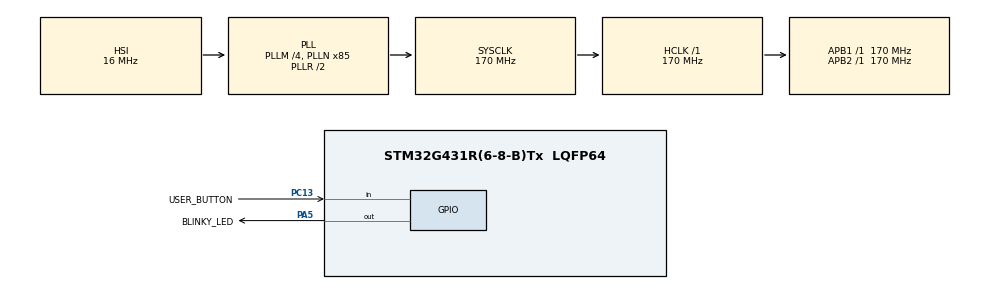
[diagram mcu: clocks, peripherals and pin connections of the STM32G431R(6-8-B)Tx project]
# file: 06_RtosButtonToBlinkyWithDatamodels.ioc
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FREERTOS.Tasks01=defaultTask,24,128,StartDefaultTask,Default,NULL,Dynamic,NULL,NULL;Input_Handler,24,128,InputHandler,Default,NULL,Dynamic,NULL,NULL;Output_Handler,24,128,OutputHandler,Default,NULL,Dynamic,NULL,NULL
FREERTOS.configUSE_NEWLIB_REENTRANT=1
Mcu.Family=STM32G4
Mcu.Name=STM32G431R(6-8-B)Tx
Mcu.Package=LQFP64
NVIC.PriorityGroup=NVIC_PRIORITYGROUP_4
NVIC.TIM1_TRG_COM_TIM17_IRQn=true\:15\:0\:false\:false\:true\:false\:false\:true\:true
NVIC.TimeBase=TIM1_TRG_COM_TIM17_IRQn
NVIC.TimeBaseIP=TIM17
PA13.GPIO_Label=T_SWDIO
PA13.Mode=Trace_Asynchronous_SW
PA13.Signal=SYS_JTMS-SWDIO
PA14.GPIO_Label=T_SWCLK
PA14.Mode=Trace_Asynchronous_SW
PA14.Signal=SYS_JTCK-SWCLK
PA2.GPIO_Label=LPUART1_TX [STLINKV3E_VCP_RX]
PA2.Signal=LPUART1_TX
PA3.GPIO_Label=LPUART1_RX [STLINKV3E_VCP_TX]
PA3.Signal=LPUART1_RX
PA5.GPIO_Label=BLINKY_LED
PA5.Signal=GPIO_Output
PB3.GPIO_Label=T_SWO
PB3.Mode=Trace_Asynchronous_SW
PB3.Signal=SYS_JTDO-SWO
PC13.GPIO_Label=USER_BUTTON
PC13.Signal=GPIO_Input
PC14-OSC32_IN.GPIO_Label=RCC_OSC32_OUT
PC14-OSC32_IN.Signal=RCC_OSC32_IN
PC15-OSC32_OUT.GPIO_Label=RCC_OSC32_OUT
PC15-OSC32_OUT.Signal=RCC_OSC32_OUT
PF0-OSC_IN.GPIO_Label=RCC_OSC_IN
PF0-OSC_IN.Signal=RCC_OSC_IN
PF1-OSC_OUT.GPIO_Label=RCC_OSC_OUT
PF1-OSC_OUT.Signal=RCC_OSC_OUT
ProjectManager.HeapSize=0x200
ProjectManager.StackSize=0x400
ProjectManager.TargetToolchain=STM32CubeIDE
RCC.ADC12Freq_Value=170000000
RCC.AHBFreq_Value=170000000
RCC.APB1Freq_Value=170000000
RCC.APB1TimFreq_Value=170000000
RCC.APB2Freq_Value=170000000
RCC.APB2TimFreq_Value=170000000
RCC.CortexFreq_Value=170000000
RCC.EXTERNAL_CLOCK_VALUE=12288000
RCC.HCLKFreq_Value=170000000
RCC.HSE_VALUE=24000000
RCC.HSI48_VALUE=48000000
RCC.HSI_VALUE=16000000
RCC.LSE_VALUE=32768
RCC.PLLM=RCC_PLLM_DIV4
RCC.PLLN=85
RCC.RTCClockSelection=RCC_RTCCLKSOURCE_LSE
RCC.SYSCLKFreq_VALUE=170000000
RCC.SYSCLKSource=RCC_SYSCLKSOURCE_PLLCLK
RCC.USBFreq_Value=170000000
RCC.VCOOutputFreq_Value=340000000
VP_FREERTOS_VS_CMSIS_V2.Mode=CMSIS_V2
VP_SYS_VS_DBSignals.Mode=DisableDeadBatterySignals
VP_SYS_VS_tim17.Mode=TIM17
board=NUCLEO-G431RB

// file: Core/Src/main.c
/* USER CODE BEGIN Header */
/**
  ******************************************************************************
  * @file           : main.c
  * @brief          : Main program body
  ******************************************************************************
  * @attention
  *
  * Copyright (c) 2025 STMicroelectronics.
  * All rights reserved.
  *
  * This software is licensed under terms that can be found in the LICENSE file
  * in the root directory of this software component.
  * If no LICENSE file comes with this software, it is provided AS-IS.
  *
  ******************************************************************************
  */
/* USER CODE END Header */
#include "main.h"
#include "cmsis_os.h"
#include "gpio.h"

void SystemClock_Config(void);
void MX_FREERTOS_Init(void);

int main(void)
{

  /* MCU Configuration--------------------------------------------------------*/

  /* Reset of all peripherals, Initializes the Flash interface and the Systick. */
  HAL_Init();

  /* Configure the system clock */
  SystemClock_Config();

  /* Initialize all configured peripherals */
  MX_GPIO_Init();

  /* Init scheduler */
  osKernelInitialize();  /* Call init function for freertos objects (in cmsis_os2.c) */
  MX_FREERTOS_Init();

  /* Start scheduler */
  osKernelStart();

  /* We should never get here as control is now taken by the scheduler */

  /* Infinite loop */
  while (1)
  {

  }
}

void SystemClock_Config(void)
{
  RCC_OscInitTypeDef RCC_OscInitStruct = {0};
  RCC_ClkInitTypeDef RCC_ClkInitStruct = {0};

  /** Configure the main internal regulator output voltage
  */
  HAL_PWREx_ControlVoltageScaling(PWR_REGULATOR_VOLTAGE_SCALE1_BOOST);

  /** Initializes the RCC Oscillators according to the specified parameters
  * in the RCC_OscInitTypeDef structure.
  */
  RCC_OscInitStruct.OscillatorType = RCC_OSCILLATORTYPE_HSI;
  RCC_OscInitStruct.HSIState = RCC_HSI_ON;
  RCC_OscInitStruct.HSICalibrationValue = RCC_HSICALIBRATION_DEFAULT;
  RCC_OscInitStruct.PLL.PLLState = RCC_PLL_ON;
  RCC_OscInitStruct.PLL.PLLSource = RCC_PLLSOURCE_HSI;
  RCC_OscInitStruct.PLL.PLLM = RCC_PLLM_DIV4;
  RCC_OscInitStruct.PLL.PLLN = 85;
  RCC_OscInitStruct.PLL.PLLP = RCC_PLLP_DIV2;
  RCC_OscInitStruct.PLL.PLLQ = RCC_PLLQ_DIV2;
  RCC_OscInitStruct.PLL.PLLR = RCC_PLLR_DIV2;
  if (HAL_RCC_OscConfig(&RCC_OscInitStruct) != HAL_OK)
  {
    Error_Handler();
  }

  /** Initializes the CPU, AHB and APB buses clocks
  */
  RCC_ClkInitStruct.ClockType = RCC_CLOCKTYPE_HCLK|RCC_CLOCKTYPE_SYSCLK
                              |RCC_CLOCKTYPE_PCLK1|RCC_CLOCKTYPE_PCLK2;
  RCC_ClkInitStruct.SYSCLKSource = RCC_SYSCLKSOURCE_PLLCLK;
  RCC_ClkInitStruct.AHBCLKDivider = RCC_SYSCLK_DIV1;
  RCC_ClkInitStruct.APB1CLKDivider = RCC_HCLK_DIV1;
  RCC_ClkInitStruct.APB2CLKDivider = RCC_HCLK_DIV1;

  if (HAL_RCC_ClockConfig(&RCC_ClkInitStruct, FLASH_LATENCY_4) != HAL_OK)
  {
    Error_Handler();
  }
}

void HAL_TIM_PeriodElapsedCallback(TIM_HandleTypeDef *htim)
{
  if (htim->Instance == TIM17)
  {
    HAL_IncTick();
  }
}

void Error_Handler(void)
{
  __disable_irq();
  while (1)
  {
  }
}

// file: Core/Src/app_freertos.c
/* USER CODE BEGIN Header */
/**
 ******************************************************************************
 * File Name          : app_freertos.c
 * Description        : Code for freertos applications
 ******************************************************************************
 * @attention
 *
 * Copyright (c) 2025 STMicroelectronics.
 * All rights reserved.
 *
 * This software is licensed under terms that can be found in the LICENSE file
 * in the root directory of this software component.
 * If no LICENSE file comes with this software, it is provided AS-IS.
 *
 ******************************************************************************
 */
/* USER CODE END Header */

#include "FreeRTOS.h"
#include "task.h"
#include "main.h"
#include "cmsis_os.h"

/* USER CODE BEGIN Includes */
#include "../../User_App/InputHandler/InputHandler.h"
#include "../../User_App/OutputHandler/OutputHandler.h"

/* USER CODE END Includes */

/* Definitions for defaultTask */
osThreadId_t defaultTaskHandle;
const osThreadAttr_t defaultTask_attributes = {
    .name = "defaultTask",
    .priority = (osPriority_t)osPriorityNormal,
    .stack_size = 128 * 4};
/* Definitions for Input_Handler */
osThreadId_t Input_HandlerHandle;
const osThreadAttr_t Input_Handler_attributes = {
    .name = "Input_Handler",
    .priority = (osPriority_t)osPriorityNormal,
    .stack_size = 128 * 4};
/* Definitions for Output_Handler */
osThreadId_t Output_HandlerHandle;
const osThreadAttr_t Output_Handler_attributes = {
    .name = "Output_Handler",
    .priority = (osPriority_t)osPriorityNormal,
    .stack_size = 128 * 4};

void StartDefaultTask(void *argument);
void InputHandler(void *argument);
void OutputHandler(void *argument);

void MX_FREERTOS_Init(void); /* (MISRA C 2004 rule 8.1) */

void MX_FREERTOS_Init(void)
{

    /* Create the thread(s) */
    /* creation of defaultTask */
    defaultTaskHandle =
        osThreadNew(StartDefaultTask, NULL, &defaultTask_attributes);

    /* creation of Input_Handler */
    Input_HandlerHandle =
        osThreadNew(InputHandler, NULL, &Input_Handler_attributes);

    /* creation of Output_Handler */
    Output_HandlerHandle =
        osThreadNew(OutputHandler, NULL, &Output_Handler_attributes);

}

void StartDefaultTask(void *argument)
{
    for (;;)
    {
        osDelay(1);
    }
}

void InputHandler(void *argument)
{
    /* USER CODE BEGIN InputHandler */
    /* Initialize the Input Handler */
    InputHandler_Init();
    /* Infinite loop */
    for (;;)
    {
        InputHandler_Loop();
        osDelay(1);
    }
    /* USER CODE END InputHandler */
}

void OutputHandler(void *argument)
{
    /* USER CODE BEGIN OutputHandler */
    OutputHandler_Init();
    /* Infinite loop */
    for (;;)
    {
        OutputHandler_Loop();
        osDelay(1);
    }
    /* USER CODE END OutputHandler */
}
